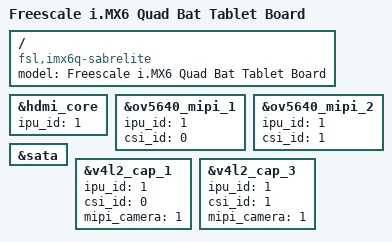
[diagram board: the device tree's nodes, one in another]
/*
 * Copyright 2013-2016 Boundary Devices, Inc.
 * Copyright 2012 Freescale Semiconductor, Inc.
 * Copyright 2011 Linaro Ltd.
 *
 * This file is dual-licensed: you can use it either under the terms
 * of the GPL or the X11 license, at your option. Note that this dual
 * licensing only applies to this file, and not this project as a
 * whole.
 *
 *  a) This file is free software; you can redistribute it and/or
 *     modify it under the terms of the GNU General Public License
 *     version 2 as published by the Free Software Foundation.
 *
 *     This file is distributed in the hope that it will be useful
 *     but WITHOUT ANY WARRANTY; without even the implied warranty of
 *     MERCHANTABILITY or FITNESS FOR A PARTICULAR PURPOSE.  See the
 *     GNU General Public License for more details.
 *
 * Or, alternatively
 *
 *  b) Permission is hereby granted, free of charge, to any person
 *     obtaining a copy of this software and associated documentation
 *     files (the "Software"), to deal in the Software without
 *     restriction, including without limitation the rights to use
 *     copy, modify, merge, publish, distribute, sublicense, and/or
 *     sell copies of the Software, and to permit persons to whom the
 *     Software is furnished to do so, subject to the following
 *     conditions:
 *
 *     The above copyright notice and this permission notice shall be
 *     included in all copies or substantial portions of the Software.
 *
 *     THE SOFTWARE IS PROVIDED , WITHOUT WARRANTY OF ANY KIND
 *     EXPRESS OR IMPLIED, INCLUDING BUT NOT LIMITED TO THE WARRANTIES
 *     OF MERCHANTABILITY, FITNESS FOR A PARTICULAR PURPOSE AND
 *     NONINFRINGEMENT. IN NO EVENT SHALL THE AUTHORS OR COPYRIGHT
 *     HOLDERS BE LIABLE FOR ANY CLAIM, DAMAGES OR OTHER LIABILITY
 *     WHETHER IN AN ACTION OF CONTRACT, TORT OR OTHERWISE, ARISING
 *     FROM, OUT OF OR IN CONNECTION WITH THE SOFTWARE OR THE USE OR
 *     OTHER DEALINGS IN THE SOFTWARE.
 */

/dts-v1/;

#include <dt-bindings/interrupt-controller/irq.h>
#include "imx6q.dtsi"
#include "imx6qdl-bat-tablet.dtsi"

/ {
	model = "Freescale i.MX6 Quad Bat Tablet Board";
	compatible = "fsl,imx6q-sabrelite", "fsl,imx6q-bat-tablet", "fsl,imx6q";
};

&hdmi_core {
	ipu_id = <1>;
};

&ov5640_mipi_1 {
	ipu_id = <1>;
	csi_id = <0>;
};

&ov5640_mipi_2 {
	ipu_id = <1>;
	csi_id = <1>;
};

&sata {
	status = "okay";
};

/* ov5640_mipi_1 */
&v4l2_cap_1 {
	ipu_id = <1>;
	csi_id = <0>;
	mipi_camera = <1>;
};

/* ov5640_mipi_2 */
&v4l2_cap_3 {
	ipu_id = <1>;
	csi_id = <1>;
	mipi_camera = <1>;
};
